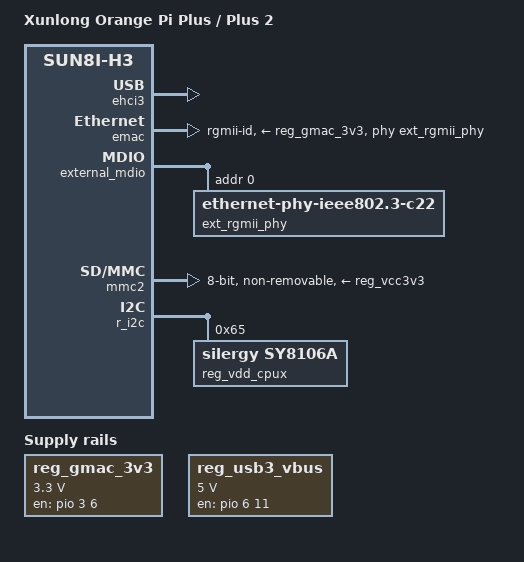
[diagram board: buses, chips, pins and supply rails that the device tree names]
#include "sun8i-h3-orangepi-2.dts"
/ {
	model = "Xunlong Orange Pi Plus / Plus 2";
	compatible = "xunlong,orangepi-plus", "allwinner,sun8i-h3";
	aliases {
		ethernet0 = &emac;
	};
	reg_gmac_3v3: gmac-3v3 {
		compatible = "regulator-fixed";
		regulator-name = "gmac-3v3";
		regulator-min-microvolt = <3300000>;
		regulator-max-microvolt = <3300000>;
		startup-delay-us = <100000>;
		enable-active-high;
		gpio = <&pio 3 6 GPIO_ACTIVE_HIGH>;
	};
	reg_usb3_vbus: usb3-vbus {
		compatible = "regulator-fixed";
		regulator-name = "usb3-vbus";
		regulator-min-microvolt = <5000000>;
		regulator-max-microvolt = <5000000>;
		regulator-boot-on;
		enable-active-high;
		gpio = <&pio 6 11 GPIO_ACTIVE_HIGH>;
	};
};
&cpu0 {
	cpu-supply = <&reg_vdd_cpux>;
};
&ehci3 {
	status = "okay";
};
&emac {
	pinctrl-names = "default";
	pinctrl-0 = <&emac_rgmii_pins>;
	phy-supply = <&reg_gmac_3v3>;
	phy-handle = <&ext_rgmii_phy>;
	phy-mode = "rgmii-id";
	status = "okay";
};
&external_mdio {
	ext_rgmii_phy: ethernet-phy@1 {
		compatible = "ethernet-phy-ieee802.3-c22";
		reg = <0>;
	};
};
&mmc2 {
	pinctrl-names = "default";
	pinctrl-0 = <&mmc2_8bit_pins>;
	vmmc-supply = <&reg_vcc3v3>;
	bus-width = <8>;
	non-removable;
	cap-mmc-hw-reset;
	status = "okay";
};
&mmc2_8bit_pins {
	drive-strength = <40>;
	bias-pull-up;
};
&r_i2c {
	status = "okay";
	reg_vdd_cpux: regulator@65 {
		compatible = "silergy,sy8106a";
		reg = <0x65>;
		regulator-name = "vdd-cpux";
		silergy,fixed-microvolt = <1200000>;
		regulator-min-microvolt = <1000000>;
		regulator-max-microvolt = <1400000>;
		regulator-ramp-delay = <200>;
		regulator-boot-on;
		regulator-always-on;
	};
};
&usbphy {
	usb3_vbus-supply = <&reg_usb3_vbus>;
};
